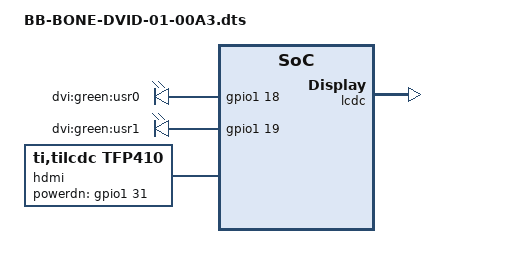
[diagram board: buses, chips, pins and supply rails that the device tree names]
/*
 * Copyright (C) 2012 Texas Instruments Incorporated - http://www.ti.com/
 *
 * This program is free software; you can redistribute it and/or modify
 * it under the terms of the GNU General Public License version 2 as
 * published by the Free Software Foundation.
 */
/dts-v1/;
/plugin/;

#include <dt-bindings/board/am335x-bbw-bbb-base.h>
#include <dt-bindings/pinctrl/am33xx.h>

/ {
	compatible = "ti,beaglebone", "ti,beaglebone-black", "ti,beaglebone-green";

	/* identification */
	part-number = "BB-BONE-DVID-01";
	version = "00A3";

	/* state the resources this cape uses */
	exclusive-use =
		/* the pin header uses */
		"P9.14",	/* led: gpio1_18 */
		"P9.16",	/* led: gpio1_19 */
		"P8.4",		/* lcd: gpio1_7 */
		"P8.45",	/* lcd: lcd_data0 */
		"P8.46",	/* lcd: lcd_data1 */
		"P8.43",	/* lcd: lcd_data2 */
		"P8.44",	/* lcd: lcd_data3 */
		"P8.41",	/* lcd: lcd_data4 */
		"P8.42",	/* lcd: lcd_data5 */
		"P8.39",	/* lcd: lcd_data6 */
		"P8.40",	/* lcd: lcd_data7 */
		"P8.37",	/* lcd: lcd_data8 */
		"P8.38",	/* lcd: lcd_data9 */
		"P8.36",	/* lcd: lcd_data10 */
		"P8.34",	/* lcd: lcd_data11 */
		"P8.35",	/* lcd: lcd_data12 */
		"P8.33",	/* lcd: lcd_data13 */
		"P8.31",	/* lcd: lcd_data14 */
		"P8.32",	/* lcd: lcd_data15 */
		"P8.27",	/* lcd: lcd_vsync */
		"P8.29",	/* lcd: lcd_hsync */
		"P8.28",	/* lcd: lcd_pclk */
		"P8.30",	/* lcd: lcd_ac_bias_en */
		/* the hardware IP uses */
		"gpio1_18",
		"gpio1_19",
		"gpio1_7",
		"lcd";

	fragment@0 {
		target = <&am33xx_pinmux>;
		__overlay__ {

			bb_lcd_led_pins: pinmux_bb_lcd_led_pins {
				pinctrl-single,pins = <
					BONE_P9_14 (PIN_OUTPUT_PULLDOWN | MUX_MODE7) /* gpmc_a2.gpio1_18 */
					BONE_P9_16 (PIN_OUTPUT_PULLDOWN | MUX_MODE7) /* gpmc_a3.gpio1_19 */
				>;
			};

			bb_lcd_pins: pinmux_bb_lcd_pins {
				pinctrl-single,pins = <

					/* Warning, P8_04 is mmc1_dat7 on BBB's eMMC, thus the output will flicker, unless eMMC is disabled... */
					BONE_P8_04 (PIN_OUTPUT_PULLDOWN | MUX_MODE7) /* gpmc_ad7.gpio1_7, OUTPUT | MODE7 - DVIPDn */

					BONE_P8_45 (PIN_OUTPUT | MUX_MODE0) /* lcd_data0.lcd_data0 */
					BONE_P8_46 (PIN_OUTPUT | MUX_MODE0) /* lcd_data1.lcd_data1 */
					BONE_P8_43 (PIN_OUTPUT | MUX_MODE0) /* lcd_data2.lcd_data2 */
					BONE_P8_44 (PIN_OUTPUT | MUX_MODE0) /* lcd_data3.lcd_data3 */
					BONE_P8_41 (PIN_OUTPUT | MUX_MODE0) /* lcd_data4.lcd_data4 */
					BONE_P8_42 (PIN_OUTPUT | MUX_MODE0) /* lcd_data5.lcd_data5 */
					BONE_P8_39 (PIN_OUTPUT | MUX_MODE0) /* lcd_data6.lcd_data6 */
					BONE_P8_40 (PIN_OUTPUT | MUX_MODE0) /* lcd_data7.lcd_data7 */
					BONE_P8_37 (PIN_OUTPUT | MUX_MODE0) /* lcd_data8.lcd_data8 */
					BONE_P8_38 (PIN_OUTPUT | MUX_MODE0) /* lcd_data9.lcd_data9 */
					BONE_P8_36 (PIN_OUTPUT | MUX_MODE0) /* lcd_data10.lcd_data10 */
					BONE_P8_34 (PIN_OUTPUT | MUX_MODE0) /* lcd_data11.lcd_data11 */
					BONE_P8_35 (PIN_OUTPUT | MUX_MODE0) /* lcd_data12.lcd_data12 */
					BONE_P8_33 (PIN_OUTPUT | MUX_MODE0) /* lcd_data13.lcd_data13 */
					BONE_P8_31 (PIN_OUTPUT | MUX_MODE0) /* lcd_data14.lcd_data14 */
					BONE_P8_32 (PIN_OUTPUT | MUX_MODE0) /* lcd_data15.lcd_data15 */

					BONE_P8_27 (PIN_OUTPUT | MUX_MODE0) /* lcd_vsync.lcd_vsync */
					BONE_P8_29 (PIN_OUTPUT | MUX_MODE0) /* lcd_hsync.lcd_hsync */
					BONE_P8_28 (PIN_OUTPUT | MUX_MODE0) /* lcd_pclk.lcd_pclk */
					BONE_P8_30 (PIN_OUTPUT | MUX_MODE0) /* lcd_ac_bias_en.lcd_ac_bias_en */
				>;
			};
		};
	};

	fragment@1 {
		target-path="/";
		__overlay__ {

			/* avoid stupid warning */
			#address-cells = <1>;
			#size-cells = <1>;

			gpio-leds-cape-dvi {
				compatible = "gpio-leds";
				pinctrl-names = "default";
				pinctrl-0 = <&bb_lcd_led_pins>;

				dvi-led0 {
					label = "dvi:green:usr0";
					gpios = <&gpio1 18 0>;
					linux,default-trigger = "heartbeat";
					default-state = "off";
				};

				dvi-led1 {
					label = "dvi:green:usr1";
					gpios = <&gpio1 19 0>;
					linux,default-trigger = "mmc0";
					default-state = "off";
				};
			};

			hdmi {
				compatible = "ti,tilcdc,tfp410";
				i2c = <&i2c2>;
				pinctrl-names = "default";
				pinctrl-0 = <&bb_lcd_pins>;
				powerdn-gpio = <&gpio1 31 0>;
				status = "okay";
			};
		};
	};

	fragment@2 {
		target = <&lcdc>;
		__overlay__ {
			status = "okay";
		};
	};
};
